# W7500x register map
Vendor: WIZnet; File version: 1.0.0
CPU: CM0 r0p0, little endian, no MPU, no FPU, 2 interrupt priority bits
Registers are 32-bit, read-write, reset 0x0 unless marked. A register's access mark holds for its fields unless they carry their own. Offsets are from the block's base; [hi:lo] are bit positions; {n}, {i} and the like mark numbered series.

## GPIOA
Base 0x42000000
Same registers: GPIOB 0x43000000, GPIOC 0x44000000, GPIOD 0x45000000
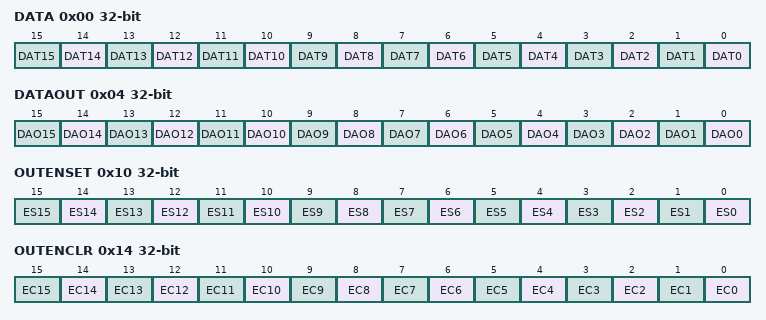
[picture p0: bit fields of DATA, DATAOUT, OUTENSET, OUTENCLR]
0x00 DATA ro
  [n] DAT{n} (n=0..15) — Port input data bit
0x04 DATAOUT — Data Output Latch register
  [n] DAO{n} (n=0..15) — Port out data bit
0x10 OUTENSET — Output Enable Set register
  [n] ES{n} (n=0..15) — sets the corresponding output enable bit, indicates the signal direction
0x14 OUTENCLR — Output Enable Clear register
  [n] EC{n} (n=0..15) — clears the output enable bit, indicates the signal direction
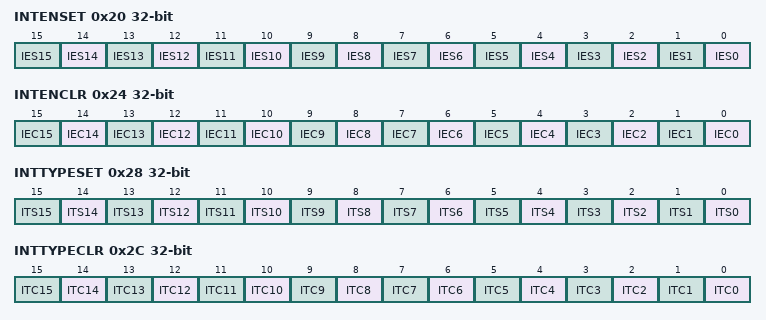
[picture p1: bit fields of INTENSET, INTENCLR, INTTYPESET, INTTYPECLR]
0x20 INTENSET — Interrupt Enable Set register
  [n] IES{n} (n=0..15) — sets the interrupt enable bit, indicates the interrupt
0x24 INTENCLR — Interrupt Enable Clear register
  [n] IEC{n} (n=0..15) — clears the interrupt enable bit, indicates the interrupt
0x28 INTTYPESET — Interrupt Type Set register
  [n] ITS{n} (n=0..15) — sets the interrupt type bit, indicates for edge or level
0x2C INTTYPECLR — Interrupt Type Clear register
  [n] ITC{n} (n=0..15) — clears the interrupt type bit, indicates for edge or level
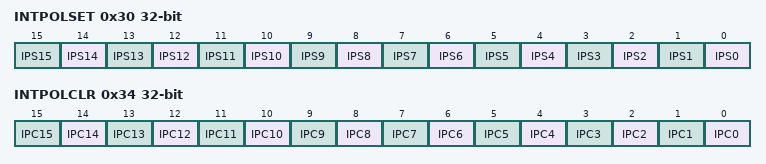
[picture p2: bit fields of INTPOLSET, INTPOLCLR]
0x30 INTPOLSET — Interrupt Polarity Set register
  [n] IPS{n} (n=0..15) — sets the interrupt polarity bit, indicates for edge or level
0x34 INTPOLCLR — Interrupt Polarity Clear register
  [n] IPC{n} (n=0..15) — clears the interrupt polarity bit, indicates for edge or level
0x38 INTSTATUS ro reset not defined — Interrupt Status register
0x38 INTCLEAR wo reset not defined — Interrupt Clear register
{0x400+4i} LB_MASKED[{i}] (i=0..255) — Lower byte Masked Access register
  [7:0] LBM — Data for lower byte access
{0x800+4i} UB_MASKED[{i}] (i=0..255) — Upper byte Masked Access register
  [15:8] HBM — Data for higher byte access

## AFC
Base 0x41002000
0x00 PA00
  [1:0] AF
    0=GPIOA_0; 2=PWM6
0x04 PA01
  [1:0] AF
    0=GPIOA_1; 2=PWM7
0x08 PA02
  [1:0] AF
    0=GPIOA_2; 2=CLKOUT
0x0C PA03
  [1:0] AF
    0=SWCLK; 3=PWM0
0x10 PA04
  [1:0] AF
    0=SWDIO; 3=PWM1
0x14 PA05
  [1:0] AF
    0=SSEL0; 2=SCL1; 3=PWM2
0x18 PA06
  [1:0] AF
    0=SCLK0; 2=SDA1; 3=PWM3
0x1C PA07
  [1:0] AF
    0=MISO0; 2=U_CTS1; 3=PWM4
0x20 PA08
  [1:0] AF
    0=MOSI0; 2=U_RTS1; 3=PWM5
0x24 PA09
  [1:0] AF
    0=SCL0; 2=U_TXD1; 3=PWM6
0x28 PA10
  [1:0] AF
    0=SDA0; 2=U_RXD1; 3=PWM7
0x2C PA11
  [1:0] AF
    0=U_CTS0; 2=SSEL1
0x30 PA12
  [1:0] AF
    0=U_RTS0; 2=SCLK1
0x34 PA13
  [1:0] AF
    0=U_TXD0; 2=MISO1
0x38 PA14
  [1:0] AF
    0=U_RXD0; 2=MOSI1
0x3C PA15
  [1:0] AF
    0=GPIOA_15
0x40 PB00
  [1:0] AF
    0=SSEL1; 1=GPIOB_0; 2=U_CTS0
0x44 PB01
  [1:0] AF
    0=SCLK1; 1=GPIOB_1; 2=U_RTS0
0x48 PB02
  [1:0] AF
    0=MISO1; 1=GPIOB_2; 2=U_TXD0
0x4C PB03
  [1:0] AF
    0=MOSI1; 1=GPIOB_3; 2=U_RXD0
0x50 PB04
  [1:0] AF
    0=TXEN; 1=GPIOB_4
0x54 PB05
  [1:0] AF
    0=COL; 1=GPIOB_5
0x58 PB06
  [1:0] AF
    0=RXD3; 1=GPIOB_6
0x5C PB07
  [1:0] AF
    0=RXCLK; 1=GPIOB_7
0x60 PB08
  [1:0] AF
    0=DUP; 1=GPIOB_8
0x64 PB09
  [1:0] AF
    0=TXCLK; 1=GPIOB_9
{0x40+4i} PB{i} (i=10..13)
  [1:0] AF
    0=TXD{i-10}; 1=GPIOB_{i}
0x78 PB14
  [1:0] AF
    0=GPIOB_14
0x7C PB15
  [1:0] AF
    0=GPIOB_15
0x80 PC00
  [1:0] AF
    0=U_CTS1; 1=GPIOC_0; 2=PWM0
0x84 PC01
  [1:0] AF
    0=U_RTS1; 1=GPIOC_1; 2=PWM1
0x88 PC02
  [1:0] AF
    0=U_TXD1; 1=GPIOC_2; 2=PWM2
0x8C PC03
  [1:0] AF
    0=U_RXD1; 1=GPIOC_3; 2=PWM3
0x90 PC04
  [1:0] AF
    0=SCL1; 1=GPIOC_4; 2=PWM4
0x94 PC05
  [1:0] AF
    0=SDA1; 1=GPIOC_5; 2=PWM5
0x98 PC06
  [1:0] AF
    0=GPIOC_6; 2=U_TXD2
0x9C PC07
  [1:0] AF
    0=GPIOC_7; 2=U_RXD2
0xA0 PC08
  [1:0] AF
    0=PWM0; 1=GPIOC_8; 2=SCL0; 3=AIN7
0xA4 PC09
  [1:0] AF
    0=PWM1; 1=GPIOC_9; 2=SDA0; 3=AIN6
0xA8 PC10
  [1:0] AF
    0=U_TXD2; 1=GPIOC_10; 2=PWM2; 3=AIN5
0xAC PC11
  [1:0] AF
    0=U_RXD2; 1=GPIOC_11; 2=PWM3; 3=AIN4
0xB0 PC12
  [1:0] AF
    0=AIN3; 1=GPIOC_12; 2=SSEL0
0xB4 PC13
  [1:0] AF
    0=AIN2; 1=GPIOC_13; 2=SCLK0
0xB8 PC14
  [1:0] AF
    0=AIN1; 1=GPIOC_14; 2=MISO0
0xBC PC15
  [1:0] AF
    0=AIN0; 1=GPIOC_15; 2=MOSI0
0xC0 PD00
  [1:0] AF
    0=CRS; 1=GPIOD_0
0xC4 PD01
  [1:0] AF
    0=RXDV; 1=GPIOD_1
{0xC0+4i} PD{i:02} (i=2..4)
  [1:0] AF
    0=RXD{i-2}; 1=GPIOD_{i}

## PAD_A
Base 0x41003000
Same registers: PAD_B 0x41003040, PAD_C 0x41003080, PAD_D 0x410030C0
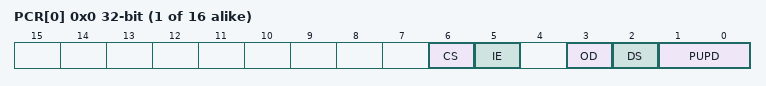
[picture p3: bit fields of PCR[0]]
{0x0+4i} PCR[{i}] (i=0..15) — PAD Control register
  [6] CS — CMOS input or Summit trigger input selection register
    0=SummitTrigger; 1=CMOS
  [5] IE — Input buffer enable selection register
  [3] OD — Open Drain output mode register
  [2] DS — Driving strength selection register
    0=High; 1=Low
  [1:0] PUPD — Pull-up, Pull-down selection register
    0=Neither; 1=PullDown; 2=PullUp
